# STM32F101_iown register map
Vendor: iown-homecontrol; Series: CM3; File version: 1.3
CPU: CM3 r1p1, little endian, no MPU, no FPU, VTOR, 4 interrupt priority bits
Registers are 32-bit, read-write, reset 0x0 unless marked. A register's access mark holds for its fields unless they carry their own. Offsets are from the block's base; [hi:lo] are bit positions; {n}, {i} and the like mark numbered series.

## OTG_FS_GLOBAL — USB on the go full speed
Base 0x50000000
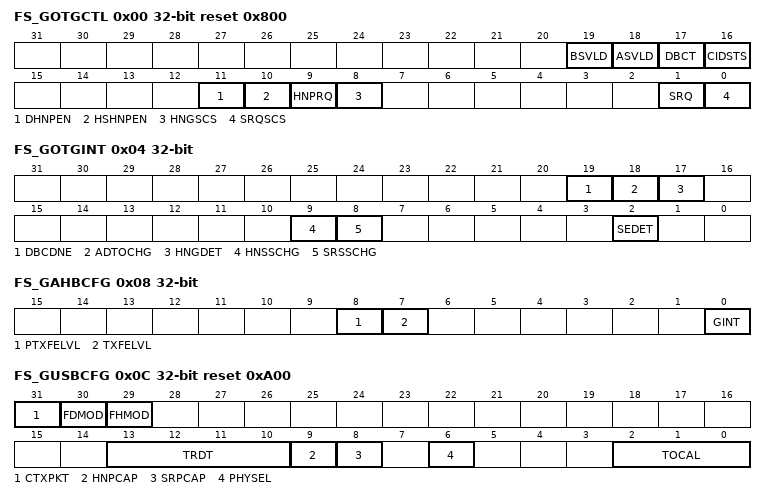
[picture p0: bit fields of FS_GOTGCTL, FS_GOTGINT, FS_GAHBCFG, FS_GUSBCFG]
0x00 FS_GOTGCTL reset 0x800 — OTG_FS control and status register (OTG_FS_GOTGCTL)
  [19] BSVLD ro — B-session valid
  [18] ASVLD ro — A-session valid
  [17] DBCT ro — Long/short debounce time
  [16] CIDSTS ro — Connector ID status
  [11] DHNPEN — Device HNP enabled
  [10] HSHNPEN — Host set HNP enable
  [9] HNPRQ — HNP request
  [8] HNGSCS ro — Host negotiation success
  [1] SRQ — Session request
  [0] SRQSCS ro — Session request success
0x04 FS_GOTGINT — OTG_FS interrupt register (OTG_FS_GOTGINT)
  [19] DBCDNE — Debounce done
  [18] ADTOCHG — A-device timeout change
  [17] HNGDET — Host negotiation detected
  [9] HNSSCHG — Host negotiation success status change
  [8] SRSSCHG — Session request success status change
  [2] SEDET — Session end detected
0x08 FS_GAHBCFG — OTG_FS AHB configuration register (OTG_FS_GAHBCFG)
  [8] PTXFELVL — Periodic TxFIFO empty level
  [7] TXFELVL — TxFIFO empty level
  [0] GINT — Global interrupt mask
0x0C FS_GUSBCFG reset 0xA00 — OTG_FS USB configuration register (OTG_FS_GUSBCFG)
  [31] CTXPKT — Corrupt Tx packet
  [30] FDMOD — Force device mode
  [29] FHMOD — Force host mode
  [13:10] TRDT — USB turnaround time
  [9] HNPCAP — HNP-capable
  [8] SRPCAP — SRP-capable
  [6] PHYSEL wo — Full Speed serial transceiver select
  [2:0] TOCAL — FS timeout calibration
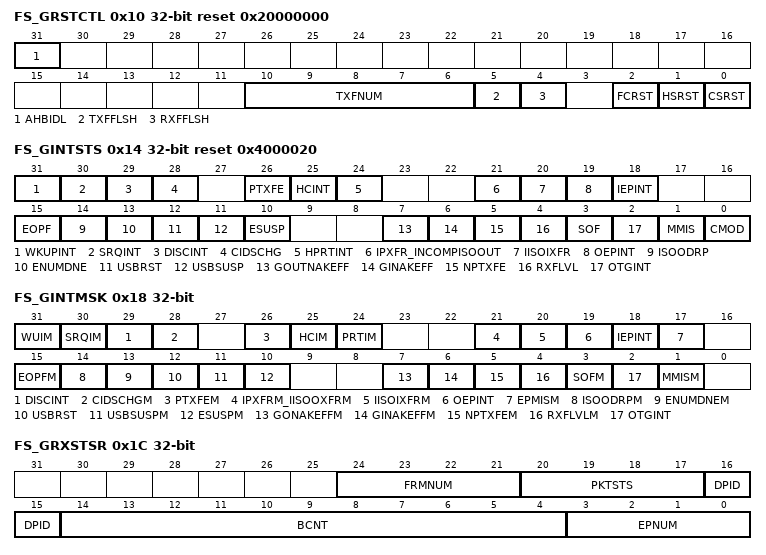
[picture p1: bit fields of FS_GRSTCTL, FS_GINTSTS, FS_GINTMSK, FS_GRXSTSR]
0x10 FS_GRSTCTL reset 0x20000000 — OTG_FS reset register (OTG_FS_GRSTCTL)
  [31] AHBIDL ro — AHB master idle
  [10:6] TXFNUM — TxFIFO number
  [5] TXFFLSH — TxFIFO flush
  [4] RXFFLSH — RxFIFO flush
  [2] FCRST — Host frame counter reset
  [1] HSRST — HCLK soft reset
  [0] CSRST — Core soft reset
0x14 FS_GINTSTS reset 0x4000020 — OTG_FS core interrupt register (OTG_FS_GINTSTS)
  [31] WKUPINT — Resume/remote wakeup detected interrupt
  [30] SRQINT — Session request/new session detected interrupt
  [29] DISCINT — Disconnect detected interrupt
  [28] CIDSCHG — Connector ID status change
  [26] PTXFE ro — Periodic TxFIFO empty
  [25] HCINT ro — Host channels interrupt
  [24] HPRTINT ro — Host port interrupt
  [21] IPXFR_INCOMPISOOUT — Incomplete periodic transfer(Host mode)/Incomplete isochronous OUT transfer(Device mode)
  [20] IISOIXFR — Incomplete isochronous IN transfer
  [19] OEPINT ro — OUT endpoint interrupt
  [18] IEPINT ro — IN endpoint interrupt
  [15] EOPF — End of periodic frame interrupt
  [14] ISOODRP — Isochronous OUT packet dropped interrupt
  [13] ENUMDNE — Enumeration done
  [12] USBRST — USB reset
  [11] USBSUSP — USB suspend
  [10] ESUSP — Early suspend
  [7] GOUTNAKEFF ro — Global OUT NAK effective
  [6] GINAKEFF ro — Global IN non-periodic NAK effective
  [5] NPTXFE ro — Non-periodic TxFIFO empty
  [4] RXFLVL ro — RxFIFO non-empty
  [3] SOF — Start of frame
  [2] OTGINT ro — OTG interrupt
  [1] MMIS — Mode mismatch interrupt
  [0] CMOD ro — Current mode of operation
0x18 FS_GINTMSK — OTG_FS interrupt mask register (OTG_FS_GINTMSK)
  [31] WUIM — Resume/remote wakeup detected interrupt mask
  [30] SRQIM — Session request/new session detected interrupt mask
  [29] DISCINT — Disconnect detected interrupt mask
  [28] CIDSCHGM — Connector ID status change mask
  [26] PTXFEM — Periodic TxFIFO empty mask
  [25] HCIM — Host channels interrupt mask
  [24] PRTIM ro — Host port interrupt mask
  [21] IPXFRM_IISOOXFRM — Incomplete periodic transfer mask(Host mode)/Incomplete isochronous OUT transfer mask(Device mode)
  [20] IISOIXFRM — Incomplete isochronous IN transfer mask
  [19] OEPINT — OUT endpoints interrupt mask
  [18] IEPINT — IN endpoints interrupt mask
  [17] EPMISM — Endpoint mismatch interrupt mask
  [15] EOPFM — End of periodic frame interrupt mask
  [14] ISOODRPM — Isochronous OUT packet dropped interrupt mask
  [13] ENUMDNEM — Enumeration done mask
  [12] USBRST — USB reset mask
  [11] USBSUSPM — USB suspend mask
  [10] ESUSPM — Early suspend mask
  [7] GONAKEFFM — Global OUT NAK effective mask
  [6] GINAKEFFM — Global non-periodic IN NAK effective mask
  [5] NPTXFEM — Non-periodic TxFIFO empty mask
  [4] RXFLVLM — Receive FIFO non-empty mask
  [3] SOFM — Start of frame mask
  [2] OTGINT — OTG interrupt mask
  [1] MMISM — Mode mismatch interrupt mask
0x1C FS_GRXSTSR ro — OTG_FS Receive status debug read
  [24:21] FRMNUM — Frame number
  [20:17] PKTSTS — Packet status
  [16:15] DPID — Data PID
  [14:4] BCNT — Byte count
  [3:0] EPNUM — Endpoint number
0x24 FS_GRXFSIZ reset 0x200 — OTG_FS Receive FIFO size register (OTG_FS_GRXFSIZ)
  [15:0] RXFD — RxFIFO depth
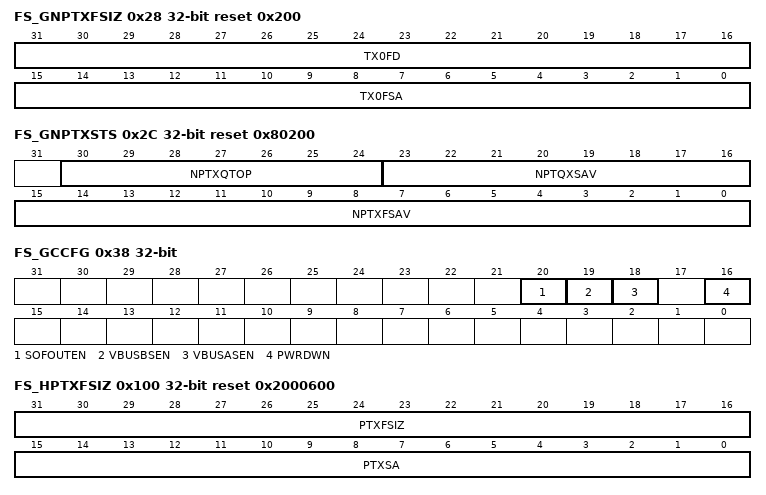
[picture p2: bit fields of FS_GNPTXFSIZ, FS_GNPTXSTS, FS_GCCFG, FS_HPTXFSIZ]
0x28 FS_GNPTXFSIZ reset 0x200 — OTG_FS non-periodic transmit FIFO size register
  [31:16] TX0FD — Endpoint 0 TxFIFO depth
  [15:0] TX0FSA — Endpoint 0 transmit RAM start address
0x2C FS_GNPTXSTS ro reset 0x80200 — OTG_FS non-periodic transmit FIFO/queue status register (OTG_FS_GNPTXSTS)
  [30:24] NPTXQTOP — Top of the non-periodic transmit request queue
  [23:16] NPTQXSAV — Non-periodic transmit request queue space available
  [15:0] NPTXFSAV — Non-periodic TxFIFO space available
0x38 FS_GCCFG — OTG_FS general core configuration register (OTG_FS_GCCFG)
  [20] SOFOUTEN — SOF output enable
  [19] VBUSBSEN — Enable the VBUS sensing device
  [18] VBUSASEN — Enable the VBUS sensing device
  [16] PWRDWN — Power down
0x3C FS_CID reset 0x1000 — core ID register
  [31:0] PRODUCT_ID
0x100 FS_HPTXFSIZ reset 0x2000600 — OTG_FS Host periodic transmit FIFO size register (OTG_FS_HPTXFSIZ)
  [31:16] PTXFSIZ — Host periodic TxFIFO depth
  [15:0] PTXSA — Host periodic TxFIFO start address
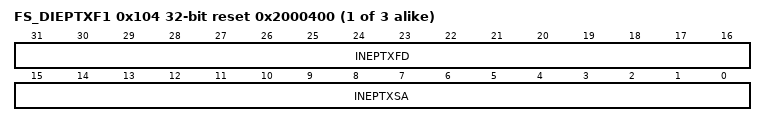
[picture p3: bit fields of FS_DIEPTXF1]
{0x100+4i} FS_DIEPTXF{i} reset 0x2000400 (i=1..3) — OTG_FS device IN endpoint transmit FIFO size register (OTG_FS_DIEPTXF{i+1})
  [31:16] INEPTXFD — IN endpoint TxFIFO depth
  [15:0] INEPTXSA — IN endpoint FIFO{i+1} transmit RAM start address
